# EHRPWM0_EHRPWM register map
Vendor: Texas Instruments
Peripheral module from a debugger description file (folder J7VCL).
Registers are 16-bit, access per field, reset 0x0 unless marked. A register's access mark holds for its fields unless they carry their own. Offsets are as the file gives them; lines under a group give offsets from that group; [hi:lo] are bit positions; {n}, {i} and the like mark numbered series; 'fields as' and 'values as' point back to an identical list; <NAME> marks a mode.

## EHRPWM0_EHRPWM
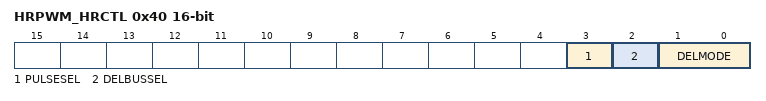
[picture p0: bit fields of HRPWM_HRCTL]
0x40 HRPWM_HRCTL — This register is only available on EPWM instances that include the high-resolution PWM (HRPWM) extension. Otherwise, this location is reserved.
  [3] PULSESEL rw — Shadow Mode Bit Selects the time event that loads the CMPAHR shadow value into the active register. The user should select this event to match the selection of the CMPA load mode 0h: Load on CTR = 0. Time-base counter equal to zero (EPWM_TBCNT = 0000h). 1h: Load on CTR = PRD. Time-base counter equal to period (EPWM_TBCNT = TEPWM_TBPRD) 2h: Load on either CTR = 0 or CTR = PRD (should not be used with HRPWM) 3h: Freeze (No loads possible should not be used with HRPWM) 0h = CTR = PRD (counter equal period) 1h = CTR = 0 (counter equals zero)
  [2] DELBUSSEL rw — Control Mode Bits Selects the register (CMP or TBPHS) that controls the MEP. 0h = Select CMPAHR(8) register controls the edge position. This is duty control mode (default on reset). 1h = Select TBPHSHR(8) register controls the edge position (this is phase control mode).
  [1:0] DELMODE rw — Edge Mode Bits Selects the edge of the PWM that is controlled by the micro-edge position (MEP) logic. 0h = HRPWM capability is disabled (default on reset) 1h = MEP control of rising edge 2h = MEP control of falling edge 3h = MEP control of both edges
